# GBA register map
File version: 0.5
Registers are 16-bit, read-write, reset 0x0 unless marked. A register's access mark holds for its fields unless they carry their own. Offsets are from the block's base; [hi:lo] are bit positions; {n}, {i} and the like mark numbered series; 'fields as' and 'values as' point back to an identical list.

## Sound — GBA Sound Controller
Base 0x04000060
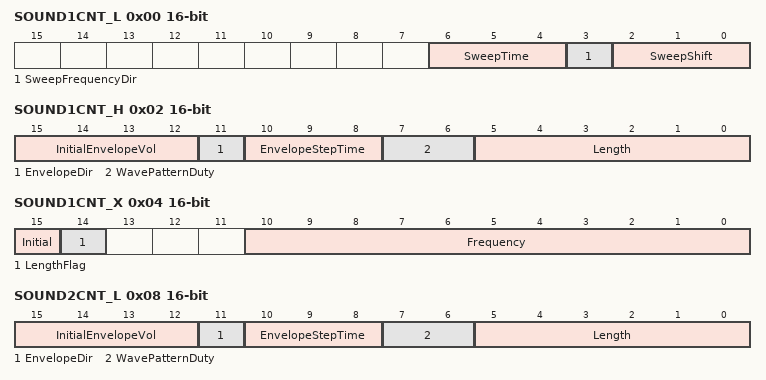
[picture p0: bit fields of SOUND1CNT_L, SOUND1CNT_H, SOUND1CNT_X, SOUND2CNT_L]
0x00 SOUND1CNT_L — Channel 1 Sweep register
  [6:4] SweepTime — Sweep Time; units of 7.8ms (0-7, min=7.8ms, max=54.7ms)
  [3] SweepFrequencyDir — Sweep Frequency Direction
    0=Increase; 1=Decrease
  [2:0] SweepShift — Number of sweep shift (n=0-7)
0x02 SOUND1CNT_H — Channel 1 Duty/Len/Envelope
  [15:12] InitialEnvelopeVol — Initial Volume of envelope (0 = No Sound)
  [11] EnvelopeDir — Envelope Direction
    0=Descrease; 1=Increase
  [10:8] EnvelopeStepTime — Envelope Step-Time; units of n/64s (0 = No Envelope)
  [7:6] WavePatternDuty
    0=Eight (12.5%); 1=Quarter (25%); 2=Half (50%); 3=ThreeQuarters (75%)
  [5:0] Length wo — Sound length; units of (64-n)/256s
0x04 SOUND1CNT_X — Channel 1 Frequency/Control
  [15] Initial wo — Initial (1=Restart Sound)
  [14] LengthFlag — Length Flag (1=Stop output when length in NR11 expires)
  [10:0] Frequency wo — Frequency; 131072/(2048-n)Hz (0-2047)
0x08 SOUND2CNT_L — Channel 2 Duty/Length/Envelope
  fields as SOUND1CNT_H
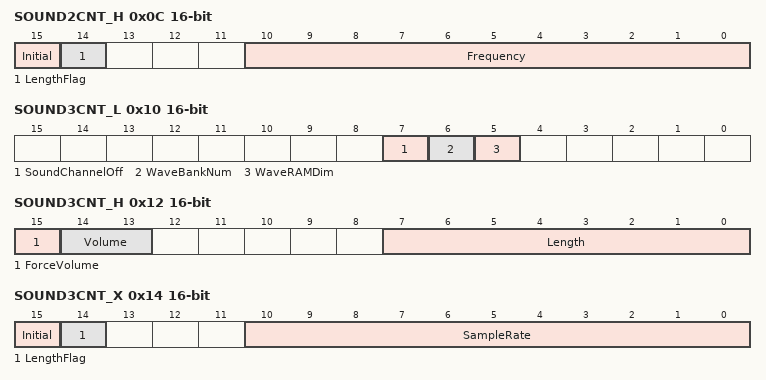
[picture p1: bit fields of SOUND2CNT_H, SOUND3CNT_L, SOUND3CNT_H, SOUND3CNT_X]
0x0C SOUND2CNT_H — Channel 2 Frequency/Control
  fields as SOUND1CNT_X
0x10 SOUND3CNT_L — Channel 3 Stop/Wave RAM select
  [7] SoundChannelOff — Sound Channel 3 Off
    0=Stop; 1=Playback
  [6] WaveBankNum — The currently selected Bank Number (Bit 6) will be played back, while reading/writing to/from wave RAM will address the other (not selected) bank. When dimension is set to two banks, output will start by replaying the currently selected bank.
  [5] WaveRAMDim — Wave RAM Dimension
    0=One bank/32 digits; 1=Two banks/64 digits
0x12 SOUND3CNT_H — Channel 3 Length/Volume
  [15] ForceVolume
    0=None (Use Volume field); 1=Force 75% regardless of Volume field
  [14:13] Volume — Sound Volume
    0=Mute; 1=Full; 2=Half; 3=Quarter
  [7:0] Length wo — Sound length; units of (256-n)/256s (0-255)
0x14 SOUND3CNT_X — Channel 3 Frequency/Control
  [15] Initial wo — Initial (1=Restart Sound)
  [14] LengthFlag — Length Flag (1=Stop output when length in NR31 expires)
  [10:0] SampleRate wo — Sample Rate; 2097152/(2048-n) Hz (0-2047)
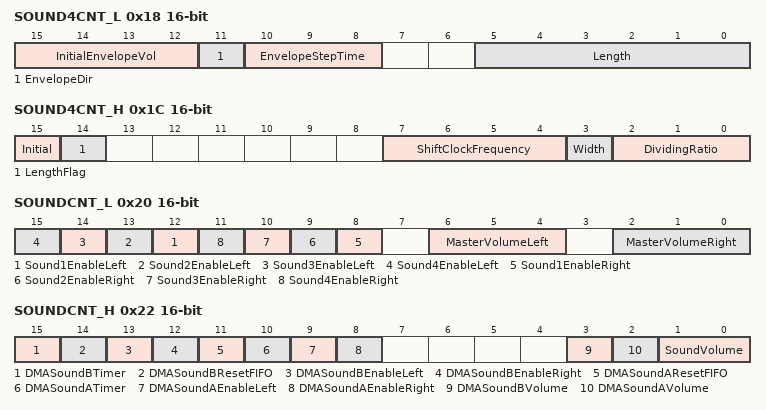
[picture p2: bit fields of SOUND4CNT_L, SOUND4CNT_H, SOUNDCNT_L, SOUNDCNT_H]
0x18 SOUND4CNT_L — Channel 4 Length/Envelope
  [15:12] InitialEnvelopeVol — Initial Volume of envelope (0 = No Sound)
  [11] EnvelopeDir — Envelope Direction
    0=Descrease; 1=Increase
  [10:8] EnvelopeStepTime — Envelope Step-Time; units of n/64s (0 = No Envelope)
  [5:0] Length wo — Sound length; units of (64-n)/256s
0x1C SOUND4CNT_H — Channel 4 Frequency/Control
  [15] Initial wo — Initial (1=Restart Sound)
  [14] LengthFlag — Length Flag (1=Stop output when length in NR41 expires)
  [7:4] ShiftClockFrequency — Shift Clock Frequency (s)
  [3] Width — Counter Step/Width
    0=Full (15 bits); 1=Half (7 bits)
  [2:0] DividingRatio — Dividing Ratio of Frequencies (r)
0x20 SOUNDCNT_L — Control Stereo/Volume/Enable
  [n+11] Sound{n}EnableLeft (n=1..4) — Enable Sound {n} Master LEFT
  [n+7] Sound{n}EnableRight (n=1..4) — Enable Sound {n} Master RIGHT
  [6:4] MasterVolumeLeft — Sound 1-4 Master Volume LEFT (0-7)
  [2:0] MasterVolumeRight — Sound 1-4 Master Volume RIGHT (0-7)
0x22 SOUNDCNT_H — DMA Sound Control/Mixing
  [15] DMASoundBTimer — DMA Sound B Reset FIFO (1=Reset)
    0=Timer0; 1=Timer1
  [14] DMASoundBResetFIFO — DMA Sound B Timer Select
  [13] DMASoundBEnableLeft
    0=Disable; 1=Enable
  [12] DMASoundBEnableRight
    0=Disable; 1=Enable
  [11] DMASoundAResetFIFO — DMA Sound A Reset FIFO (1=Reset)
  [10] DMASoundATimer — DMA Sound A Timer Select
    0=Timer0; 1=Timer1
  [9] DMASoundAEnableLeft
    0=Disable; 1=Enable
  [8] DMASoundAEnableRight
    0=Disable; 1=Enable
  [3] DMASoundBVolume
    0=Half; 1=Full
  [2] DMASoundAVolume
    0=Half; 1=Full
  [1:0] SoundVolume — Sound # 1-4 Volume
    0=Quarter; 1=Half; 2=Full; 3=Prohibited
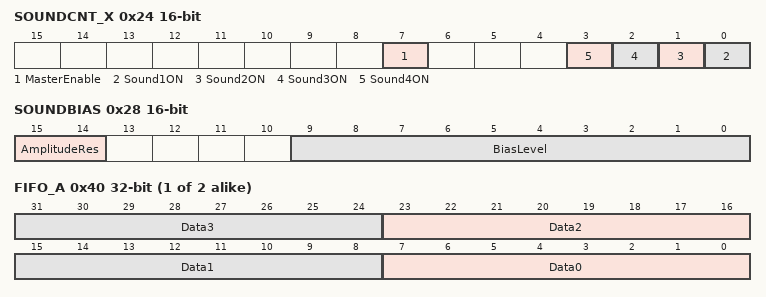
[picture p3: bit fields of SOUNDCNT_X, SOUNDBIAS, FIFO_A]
0x24 SOUNDCNT_X — Sound on/off
  [7] MasterEnable — PSG/FIFO Master Enable
    0=Disable; 1=Enable
  [n-1] Sound{n}ON ro (n=1..4) — Sound {n} ON flag
0x28 SOUNDBIAS — Sound PWM Control
  [15:14] AmplitudeRes — Amplitude Resolution/Sampling Cycle (Default=0)
    0=Cycle0 (9bit / 32.768kHz (Default, best for DMA channels A,B)); 1=Cycle1 (8bit / 65.536kHz); 2=Cycle2 (7bit / 131.072kHz); 3=Cycle3 (6bit / 262.144kHz (Best for PSG channels 1-4))
  [9:0] BiasLevel — Bias Level (Default=200h, converting signed samples into unsigned)
{0x30+4i} WAVE_RAM{i} (i=0..3) 32-bit — This area contains 16 bytes (32 x 4bits) Wave Pattern data which is output by channel 3.
0x40 FIFO_{x} (x=A,B; step 0x4) 32-bit wo — Sound [{x}] FIFO
  [8n+7:8n] Data{n} (n=0..3)
